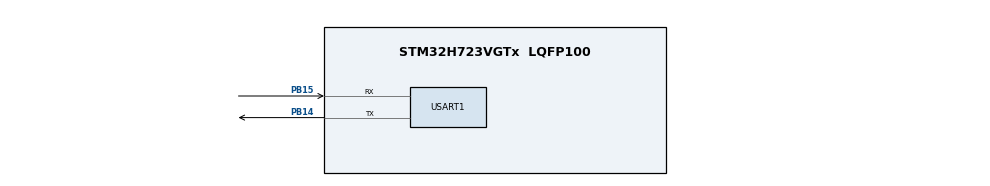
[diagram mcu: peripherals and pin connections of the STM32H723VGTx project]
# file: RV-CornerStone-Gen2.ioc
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CORTEX_M7.CPU_ICache=Enabled
CORTEX_M7.Enable_Spec=__NULL
CORTEX_M7.MPU_Control=__NULL
CORTEX_M7.default_mode_Activation=1
Dma.Request0=USART1_TX
Dma.USART1_TX.0.Direction=DMA_MEMORY_TO_PERIPH
Dma.USART1_TX.0.EventEnable=DISABLE
Dma.USART1_TX.0.FIFOMode=DMA_FIFOMODE_DISABLE
Dma.USART1_TX.0.Instance=DMA1_Stream0
Dma.USART1_TX.0.MemDataAlignment=DMA_MDATAALIGN_BYTE
Dma.USART1_TX.0.MemInc=DMA_MINC_ENABLE
Dma.USART1_TX.0.Mode=DMA_NORMAL
Dma.USART1_TX.0.PeriphDataAlignment=DMA_PDATAALIGN_BYTE
Dma.USART1_TX.0.PeriphInc=DMA_PINC_DISABLE
Dma.USART1_TX.0.Polarity=HAL_DMAMUX_REQ_GEN_RISING
Dma.USART1_TX.0.Priority=DMA_PRIORITY_LOW
Dma.USART1_TX.0.RequestNumber=1
Dma.USART1_TX.0.SignalID=NONE
Dma.USART1_TX.0.SyncEnable=DISABLE
Dma.USART1_TX.0.SyncPolarity=HAL_DMAMUX_SYNC_NO_EVENT
Dma.USART1_TX.0.SyncRequestNumber=1
Dma.USART1_TX.0.SyncSignalID=NONE
FREERTOS.Tasks01=defaultTask,24,128,StartDefaultTask,Default,NULL,Dynamic,NULL,NULL
FREERTOS.configENABLE_FPU=1
Mcu.Family=STM32H7
Mcu.Name=STM32H723VGTx
Mcu.Package=LQFP100
NVIC.DMA1_Stream0_IRQn=true\:5\:0\:false\:false\:true\:true\:false\:true\:true
NVIC.PriorityGroup=NVIC_PRIORITYGROUP_4
NVIC.TIM6_DAC_IRQn=true\:15\:0\:false\:false\:true\:false\:false\:true\:true
NVIC.TimeBase=TIM6_DAC_IRQn
NVIC.TimeBaseIP=TIM6
PA13(JTMS/SWDIO).Mode=Serial_Wire
PA13(JTMS/SWDIO).Signal=DEBUG_JTMS-SWDIO
PA14(JTCK/SWCLK).Mode=Serial_Wire
PA14(JTCK/SWCLK).Signal=DEBUG_JTCK-SWCLK
PB14.Mode=Asynchronous
PB14.Signal=USART1_TX
PB15.Mode=Asynchronous
PB15.Signal=USART1_RX
PH0-OSC_IN.Mode=HSE-External-Oscillator
PH0-OSC_IN.Signal=RCC_OSC_IN
PH1-OSC_OUT.Mode=HSE-External-Oscillator
PH1-OSC_OUT.Signal=RCC_OSC_OUT
ProjectManager.HeapSize=0x200
ProjectManager.StackSize=0x400
ProjectManager.TargetToolchain=CMake
RCC.ADCFreq_Value=48375000
RCC.APB1Freq_Value=137500000
RCC.APB2Freq_Value=137500000
RCC.APB3Freq_Value=137500000
RCC.APB4Freq_Value=137500000
RCC.CortexFreq_Value=550000000
RCC.D1PPRE=RCC_APB3_DIV2
RCC.D2PPRE1=RCC_APB1_DIV2
RCC.D2PPRE2=RCC_APB2_DIV2
RCC.D3PPRE=RCC_APB4_DIV2
RCC.DIVM1=3
RCC.DIVN1=68
RCC.DIVP1=1
RCC.HCLKFreq_Value=275000000
RCC.HPRE=RCC_HCLK_DIV2
RCC.HSE_VALUE=24000000
RCC.PLL2FRACN=0
RCC.PLL3FRACN=0
RCC.PLLFRACN=6144
RCC.PLLSourceVirtual=RCC_PLLSOURCE_HSE
RCC.SYSCLKFreq_VALUE=550000000
RCC.SYSCLKSource=RCC_SYSCLKSOURCE_PLLCLK
RCC.USBFreq_Value=275000000
USART1.VirtualMode-Asynchronous=VM_ASYNC
VP_FREERTOS_VS_CMSIS_V2.Mode=CMSIS_V2
VP_MEMORYMAP_VS_MEMORYMAP.Mode=CurAppReg
VP_SYS_VS_tim6.Mode=TIM6
board=custom

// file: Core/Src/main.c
/* USER CODE BEGIN Header */
/**
  ******************************************************************************
  * @file           : main.c
  * @brief          : Main program body
  ******************************************************************************
  * @attention
  *
  * Copyright (c) 2026 STMicroelectronics.
  * All rights reserved.
  *
  * This software is licensed under terms that can be found in the LICENSE file
  * in the root directory of this software component.
  * If no LICENSE file comes with this software, it is provided AS-IS.
  *
  ******************************************************************************
  */
/* USER CODE END Header */
#include "main.h"
#include "cmsis_os.h"
#include "dma.h"
#include "usart.h"
#include "gpio.h"

/* USER CODE BEGIN Includes */
#include "cpp_init.h"
/* USER CODE END Includes */

void SystemClock_Config(void);
void MX_FREERTOS_Init(void);

int main(void)
{

  /* Enable the CPU Cache */

  /* Enable I-Cache---------------------------------------------------------*/
  SCB_EnableICache();

  /* MCU Configuration--------------------------------------------------------*/

  /* Reset of all peripherals, Initializes the Flash interface and the Systick. */
  HAL_Init();

  /* Configure the system clock */
  SystemClock_Config();

  /* Initialize all configured peripherals */
  MX_GPIO_Init();
  MX_DMA_Init();
  MX_USART1_UART_Init();
  /* USER CODE BEGIN 2 */
  cpp_init();
  /* USER CODE END 2 */

  /* Init scheduler */
  osKernelInitialize();  /* Call init function for freertos objects (in cmsis_os2.c) */
  MX_FREERTOS_Init();

  /* Start scheduler */
  osKernelStart();

  /* We should never get here as control is now taken by the scheduler */

  /* Infinite loop */
  while (1)
  {

  }
}

void SystemClock_Config(void)
{
  RCC_OscInitTypeDef RCC_OscInitStruct = {0};
  RCC_ClkInitTypeDef RCC_ClkInitStruct = {0};

  /** Supply configuration update enable
  */
  HAL_PWREx_ConfigSupply(PWR_LDO_SUPPLY);

  /** Configure the main internal regulator output voltage
  */
  __HAL_PWR_VOLTAGESCALING_CONFIG(PWR_REGULATOR_VOLTAGE_SCALE0);

  while(!__HAL_PWR_GET_FLAG(PWR_FLAG_VOSRDY)) {}

  /** Initializes the RCC Oscillators according to the specified parameters
  * in the RCC_OscInitTypeDef structure.
  */
  RCC_OscInitStruct.OscillatorType = RCC_OSCILLATORTYPE_HSE;
  RCC_OscInitStruct.HSEState = RCC_HSE_ON;
  RCC_OscInitStruct.PLL.PLLState = RCC_PLL_ON;
  RCC_OscInitStruct.PLL.PLLSource = RCC_PLLSOURCE_HSE;
  RCC_OscInitStruct.PLL.PLLM = 3;
  RCC_OscInitStruct.PLL.PLLN = 68;
  RCC_OscInitStruct.PLL.PLLP = 1;
  RCC_OscInitStruct.PLL.PLLQ = 2;
  RCC_OscInitStruct.PLL.PLLR = 2;
  RCC_OscInitStruct.PLL.PLLRGE = RCC_PLL1VCIRANGE_3;
  RCC_OscInitStruct.PLL.PLLVCOSEL = RCC_PLL1VCOWIDE;
  RCC_OscInitStruct.PLL.PLLFRACN = 6144;
  if (HAL_RCC_OscConfig(&RCC_OscInitStruct) != HAL_OK)
  {
    Error_Handler();
  }

  /** Initializes the CPU, AHB and APB buses clocks
  */
  RCC_ClkInitStruct.ClockType = RCC_CLOCKTYPE_HCLK|RCC_CLOCKTYPE_SYSCLK
                              |RCC_CLOCKTYPE_PCLK1|RCC_CLOCKTYPE_PCLK2
                              |RCC_CLOCKTYPE_D3PCLK1|RCC_CLOCKTYPE_D1PCLK1;
  RCC_ClkInitStruct.SYSCLKSource = RCC_SYSCLKSOURCE_PLLCLK;
  RCC_ClkInitStruct.SYSCLKDivider = RCC_SYSCLK_DIV1;
  RCC_ClkInitStruct.AHBCLKDivider = RCC_HCLK_DIV2;
  RCC_ClkInitStruct.APB3CLKDivider = RCC_APB3_DIV2;
  RCC_ClkInitStruct.APB1CLKDivider = RCC_APB1_DIV2;
  RCC_ClkInitStruct.APB2CLKDivider = RCC_APB2_DIV2;
  RCC_ClkInitStruct.APB4CLKDivider = RCC_APB4_DIV2;

  if (HAL_RCC_ClockConfig(&RCC_ClkInitStruct, FLASH_LATENCY_3) != HAL_OK)
  {
    Error_Handler();
  }
}

void HAL_TIM_PeriodElapsedCallback(TIM_HandleTypeDef *htim)
{
  if (htim->Instance == TIM6)
  {
    HAL_IncTick();
  }
}

void Error_Handler(void)
{
  __disable_irq();
  while (1)
  {
  }
}
